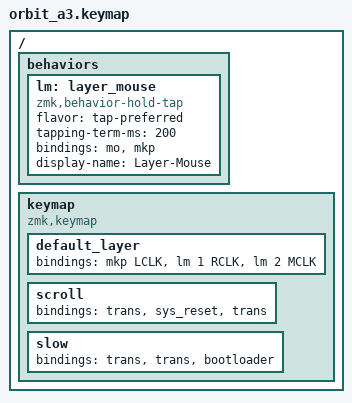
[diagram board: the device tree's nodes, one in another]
#include <behaviors.dtsi>
#include <dt-bindings/zmk/pointing.h>

/ {
    behaviors {
        lm: layer_mouse {
            compatible = "zmk,behavior-hold-tap";
            #binding-cells = <2>;
            flavor = "tap-preferred";
            tapping-term-ms = <200>;
            bindings = <&mo>, <&mkp>;
            display-name = "Layer-Mouse";
        };
    };

    keymap {
        compatible = "zmk,keymap";

        default_layer {
            // | BTN1    | BTN2     | BTN3     |
            bindings = <
                &mkp LCLK &lm 1 RCLK &lm 2 MCLK
            >;
        };

        scroll {
            bindings = <
                &trans &sys_reset &trans
            >;
        };

        slow {
            bindings = <
                &trans &trans &bootloader
            >;
        };
    };
};
